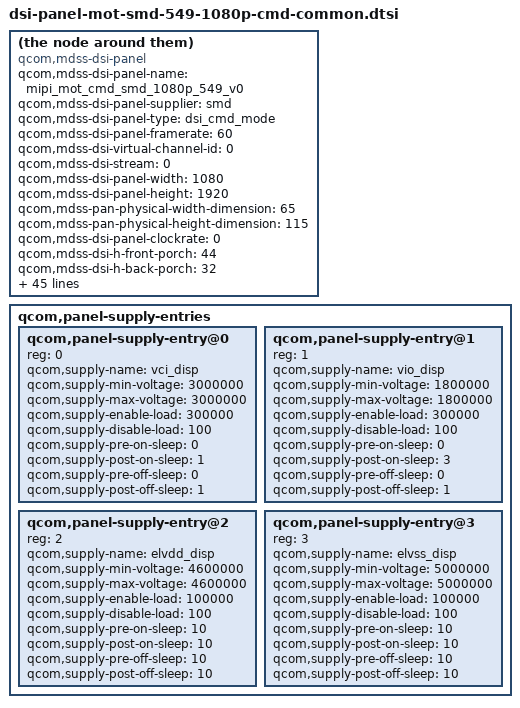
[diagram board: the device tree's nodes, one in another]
/* Copyright (c) 2016, The Linux Foundation. All rights reserved.
 *
 * This program is free software; you can redistribute it and/or modify
 * it under the terms of the GNU General Public License version 2 and
 * only version 2 as published by the Free Software Foundation.
 *
 * This program is distributed in the hope that it will be useful,
 * but WITHOUT ANY WARRANTY; without even the implied warranty of
 * MERCHANTABILITY or FITNESS FOR A PARTICULAR PURPOSE.  See the
 * GNU General Public License for more details.
 */

compatible = "qcom,mdss-dsi-panel";
qcom,mdss-dsi-panel-name = "mipi_mot_cmd_smd_1080p_549_v0";
qcom,mdss-dsi-panel-supplier = "smd";
qcom,mdss-dsi-panel-type = "dsi_cmd_mode";
qcom,mdss-dsi-panel-framerate = <60>;
qcom,mdss-dsi-virtual-channel-id = <0>;
qcom,mdss-dsi-stream = <0>;
qcom,mdss-dsi-panel-width = <1080>;
qcom,mdss-dsi-panel-height = <1920>;
/* To update dimension based on final spec */
qcom,mdss-pan-physical-width-dimension = <65>;
qcom,mdss-pan-physical-height-dimension = <115>;

/* To update clock rate */
qcom,mdss-dsi-panel-clockrate = <0>;
qcom,mdss-dsi-h-front-porch = <44>;
qcom,mdss-dsi-h-back-porch = <32>;
qcom,mdss-dsi-h-pulse-width = <12>;
qcom,mdss-dsi-h-sync-skew = <0>;
qcom,mdss-dsi-v-back-porch = <3>;
qcom,mdss-dsi-v-front-porch = <9>;
qcom,mdss-dsi-v-pulse-width = <4>;
qcom,mdss-dsi-h-left-border = <0>;
qcom,mdss-dsi-h-right-border = <0>;
qcom,mdss-dsi-v-top-border = <0>;
qcom,mdss-dsi-v-bottom-border = <0>;
qcom,mdss-dsi-bpp = <24>;
qcom,mdss-dsi-underflow-color = <0xff>;
qcom,mdss-dsi-border-color = <0>;
qcom,mdss-dsi-on-command = [
	05 01 00 00 78 00 01 11
	29 01 00 00 00 00 03 fc 5a 5a
	29 01 00 00 00 00 03 f4 00 01
	15 01 00 00 00 00 02 57 00
	29 01 00 00 00 00 03 fc a5 a5
	15 01 00 00 00 00 02 53 20
	15 01 00 00 00 00 02 55 00
	15 01 00 00 00 00 02 51 00
	05 01 00 00 00 00 01 29];	/* display on */
qcom,mdss-dsi-off-command = [
	05 01 00 00 0a 00 01 28		/* display_off */
	05 01 00 00 55 00 01 10];	/* enter sleep mode */

qcom,mdss-dsi-on-command-state = "dsi_lp_mode";
qcom,mdss-dsi-off-command-state = "dsi_lp_mode";
qcom,mdss-dsi-h-sync-pulse = <0>;
qcom,mdss-dsi-traffic-mode = "burst_mode";
qcom,mdss-dsi-bllp-eof-power-mode;
qcom,mdss-dsi-bllp-power-mode;
qcom,mdss-dsi-lane-0-state;
qcom,mdss-dsi-lane-1-state;
qcom,mdss-dsi-lane-2-state;
qcom,mdss-dsi-lane-3-state;
/* To caculate timing with final clock rate setting */
qcom,mdss-dsi-panel-timings-8996 =
				[22 1e 07 08 04 03 04 a0
				22 1e 07 08 04 03 04 a0
				22 1e 07 08 04 03 04 a0
				22 1e 07 08 04 03 04 a0
				22 18 07 08 04 03 04 a0];
qcom,mdss-dsi-panel-timings = [d5 32 22 00 60 62 26 34 29 03 04 00];
qcom,mdss-dsi-t-clk-post = <0x03>;
qcom,mdss-dsi-t-clk-pre = <0x28>;
qcom,mdss-dsi-bl-min-level = <1>;
qcom,mdss-dsi-bl-max-level = <255>;
qcom,mdss-dsi-dma-trigger = "trigger_sw";
qcom,mdss-dsi-mdp-trigger = "none";
qcom,mdss-dsi-bl-pmic-control-type = "bl_ctrl_dcs";
qcom,mdss-dsi-reset-sequence = <1 11>;
qcom,mdss-dsi-lp11-init;
qcom,mdss-dsi-tx-eot-append;

qcom,mdss-dsi-te-pin-select = <1>;
qcom,mdss-dsi-te-dcs-command = <1>;
qcom,mdss-dsi-te-check-enable;
qcom,mdss-dsi-te-using-te-pin;

qcom,panel-supply-entries {
	#address-cells = <1>;
	#size-cells = <0>;

	qcom,panel-supply-entry@0 {
		reg = <0>;
		qcom,supply-name = "vci_disp";
		qcom,supply-min-voltage = <3000000>;
		qcom,supply-max-voltage = <3000000>;
		qcom,supply-enable-load = <300000>;
		qcom,supply-disable-load = <100>;
		qcom,supply-pre-on-sleep = <0>;
		qcom,supply-post-on-sleep = <1>;
		qcom,supply-pre-off-sleep = <0>;
		qcom,supply-post-off-sleep = <1>;
	}
;
	qcom,panel-supply-entry@1 {
		reg = <1>;
		qcom,supply-name = "vio_disp";
		qcom,supply-min-voltage = <1800000>;
		qcom,supply-max-voltage = <1800000>;
		qcom,supply-enable-load = <300000>;
		qcom,supply-disable-load = <100>;
		qcom,supply-pre-on-sleep = <0>;
		qcom,supply-post-on-sleep = <3>;
		qcom,supply-pre-off-sleep = <0>;
		qcom,supply-post-off-sleep = <1>;
	};

	qcom,panel-supply-entry@2 {
		reg = <2>;
		qcom,supply-name = "elvdd_disp";
		qcom,supply-min-voltage = <4600000>;
		qcom,supply-max-voltage = <4600000>;
		qcom,supply-enable-load = <100000>;
		qcom,supply-disable-load = <100>;
		qcom,supply-pre-on-sleep = <10>;
		qcom,supply-post-on-sleep = <10>;
		qcom,supply-pre-off-sleep = <10>;
		qcom,supply-post-off-sleep = <10>;
	};

	qcom,panel-supply-entry@3 {
		reg = <3>;
		qcom,supply-name = "elvss_disp";
		qcom,supply-min-voltage = <5000000>;
		qcom,supply-max-voltage = <5000000>;
		qcom,supply-enable-load = <100000>;
		qcom,supply-disable-load = <100>;
		qcom,supply-pre-on-sleep = <10>;
		qcom,supply-post-on-sleep = <10>;
		qcom,supply-pre-off-sleep = <10>;
		qcom,supply-post-off-sleep = <10>;
	};
};
